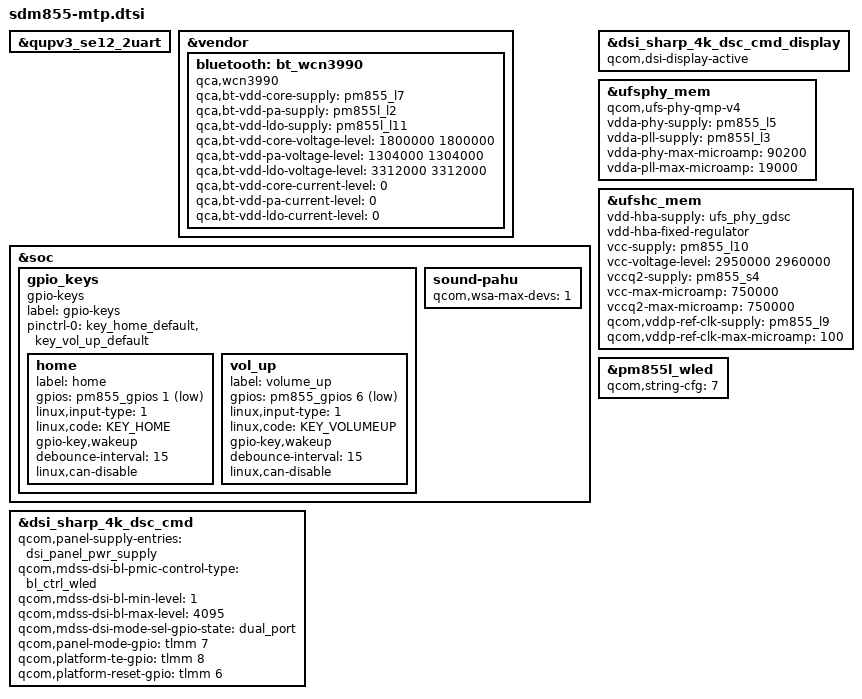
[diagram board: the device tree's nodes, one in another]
/* Copyright (c) 2017-2018, The Linux Foundation. All rights reserved.
 *
 * This program is free software; you can redistribute it and/or modify
 * it under the terms of the GNU General Public License version 2 and
 * only version 2 as published by the Free Software Foundation.
 *
 * This program is distributed in the hope that it will be useful,
 * but WITHOUT ANY WARRANTY; without even the implied warranty of
 * MERCHANTABILITY or FITNESS FOR A PARTICULAR PURPOSE.  See the
 * GNU General Public License for more details.
 */

#include <dt-bindings/gpio/gpio.h>
#include <dt-bindings/input/input.h>

#include "sdm855-pmic-overlay.dtsi"
#include "sdm855-audio-overlay.dtsi"
#include "sdm855-sde-display.dtsi"

&qupv3_se12_2uart {
	status = "ok";
};

&vendor {
	bluetooth: bt_wcn3990 {
		compatible = "qca,wcn3990";
		qca,bt-vdd-core-supply = <&pm855_l7>;
		qca,bt-vdd-pa-supply = <&pm855l_l2>;
		qca,bt-vdd-ldo-supply = <&pm855l_l11>;

		qca,bt-vdd-core-voltage-level = <1800000 1800000>;
		qca,bt-vdd-pa-voltage-level = <1304000 1304000>;
		qca,bt-vdd-ldo-voltage-level = <3312000 3312000>;

		qca,bt-vdd-core-current-level = <0>; /* LPM/PFM */
		qca,bt-vdd-pa-current-level = <0>; /* LPM/PFM */
		qca,bt-vdd-ldo-current-level = <0>; /* LPM/PFM */
	};
};

&soc {
	gpio_keys {
		compatible = "gpio-keys";
		label = "gpio-keys";

		pinctrl-names = "default";
		pinctrl-0 = <&key_home_default
			     &key_vol_up_default>;

		home {
			label = "home";
			gpios = <&pm855_gpios 1 GPIO_ACTIVE_LOW>;
			linux,input-type = <1>;
			linux,code = <KEY_HOME>;
			gpio-key,wakeup;
			debounce-interval = <15>;
			linux,can-disable;
		};

		vol_up {
			label = "volume_up";
			gpios = <&pm855_gpios 6 GPIO_ACTIVE_LOW>;
			linux,input-type = <1>;
			linux,code = <KEY_VOLUMEUP>;
			gpio-key,wakeup;
			debounce-interval = <15>;
			linux,can-disable;
		};
	};

	sound-pahu {
		qcom,wsa-max-devs = <1>;
	};
};

&dsi_sharp_4k_dsc_cmd {
	qcom,panel-supply-entries = <&dsi_panel_pwr_supply>;
	qcom,mdss-dsi-bl-pmic-control-type = "bl_ctrl_wled";
	qcom,mdss-dsi-bl-min-level = <1>;
	qcom,mdss-dsi-bl-max-level = <4095>;
	qcom,mdss-dsi-mode-sel-gpio-state = "dual_port";
	qcom,panel-mode-gpio = <&tlmm 7 0>;
	qcom,platform-te-gpio = <&tlmm 8 0>;
	qcom,platform-reset-gpio = <&tlmm 6 0>;
};

&dsi_sharp_4k_dsc_cmd_display {
	qcom,dsi-display-active;
};

&ufsphy_mem {
	compatible = "qcom,ufs-phy-qmp-v4";

	vdda-phy-supply = <&pm855_l5>;
	vdda-pll-supply = <&pm855l_l3>;
	vdda-phy-max-microamp = <90200>;
	vdda-pll-max-microamp = <19000>;

	status = "ok";
};

&ufshc_mem {
	vdd-hba-supply = <&ufs_phy_gdsc>;
	vdd-hba-fixed-regulator;
	vcc-supply = <&pm855_l10>;
	vcc-voltage-level = <2950000 2960000>;
	vccq2-supply = <&pm855_s4>;
	vcc-max-microamp = <750000>;
	vccq2-max-microamp = <750000>;

	qcom,vddp-ref-clk-supply = <&pm855_l9>;
	qcom,vddp-ref-clk-max-microamp = <100>;

	status = "ok";
};

&pm855l_wled {
	qcom,string-cfg= <7>;
	status = "ok";
};
